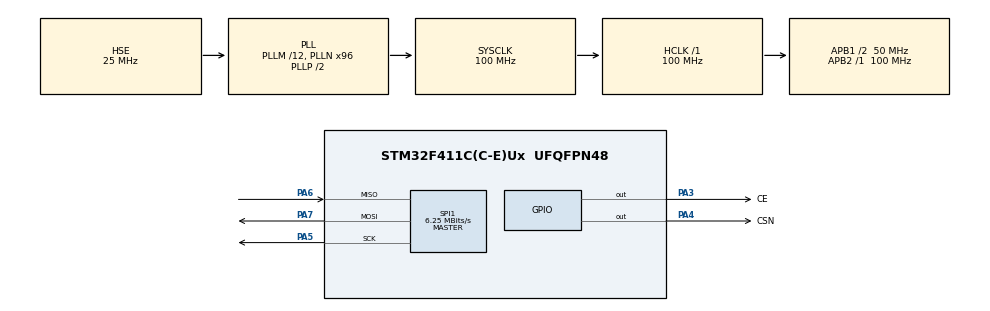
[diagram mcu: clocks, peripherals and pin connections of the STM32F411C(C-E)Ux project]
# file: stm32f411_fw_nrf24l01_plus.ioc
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Mcu.Family=STM32F4
RCC.PLLSourceVirtual=RCC_PLLSOURCE_HSE
PC15-OSC32_OUT.Mode=LSE-External-Oscillator
PA6.Mode=Full_Duplex_Master
RCC.CortexFreq_Value=100000000
PA7.Mode=Full_Duplex_Master
SPI1.VirtualType=VM_MASTER
PH1\ -\ OSC_OUT.Mode=HSE-External-Oscillator
RCC.APB1CLKDivider=RCC_HCLK_DIV2
PC14-OSC32_IN.Signal=RCC_OSC32_IN
PA3.GPIO_Speed=GPIO_SPEED_FREQ_HIGH
RCC.SYSCLKSource=RCC_SYSCLKSOURCE_PLLCLK
ProjectManager.StackSize=0x400
PA13.Signal=SYS_JTMS-SWDIO
PH0\ -\ OSC_IN.Mode=HSE-External-Oscillator
PA4.PinState=GPIO_PIN_SET
PH0\ -\ OSC_IN.Signal=RCC_OSC_IN
ProjectManager.TargetToolchain=STM32CubeIDE
SPI1.Direction=SPI_DIRECTION_2LINES
RCC.HCLKFreq_Value=100000000
RCC.APB2TimFreq_Value=100000000
SPI1.CalculateBaudRate=6.25 MBits/s
PC15-OSC32_OUT.Signal=RCC_OSC32_OUT
RCC.AHBFreq_Value=100000000
PA5.Signal=SPI1_SCK
RCC.HSE_VALUE=25000000
PH1\ -\ OSC_OUT.Signal=RCC_OSC_OUT
board=custom
RCC.VCOOutputFreq_Value=200000000
PA4.GPIO_Speed=GPIO_SPEED_FREQ_HIGH
RCC.APB2Freq_Value=100000000
PC14-OSC32_IN.Mode=LSE-External-Oscillator
SPI1.Mode=SPI_MODE_MASTER
PA14.Mode=Serial_Wire
PA13.Mode=Serial_Wire
Mcu.Name=STM32F411C(C-E)Ux
RCC.48MHZClocksFreq_Value=50000000
PA4.Signal=GPIO_Output
RCC.SYSCLKFreq_VALUE=100000000
Mcu.Package=UFQFPN48
PA6.Signal=SPI1_MISO
PA14.Signal=SYS_JTCK-SWCLK
ProjectManager.HeapSize=0x200
RCC.HSI_VALUE=16000000
NVIC.PriorityGroup=NVIC_PRIORITYGROUP_4
RCC.PLLM=12
RCC.PLLN=96
RCC.APB1TimFreq_Value=100000000
RCC.APB1Freq_Value=50000000
SPI1.BaudRatePrescaler=SPI_BAUDRATEPRESCALER_16
PA4.GPIO_Label=CSN
PA3.GPIO_Label=CE
PA3.Signal=GPIO_Output
PA5.Mode=Full_Duplex_Master
PA7.Signal=SPI1_MOSI

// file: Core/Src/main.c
/* USER CODE BEGIN Header */
/**
  ******************************************************************************
  * @file           : main.c
  * @brief          : Main program body
  ******************************************************************************
  * @attention
  *
  * <h2><center>&copy; Copyright (c) 2021 STMicroelectronics.
  * All rights reserved.</center></h2>
  *
  * This software component is licensed by ST under BSD 3-Clause license,
  * the "License"; You may not use this file except in compliance with the
  * License. You may obtain a copy of the License at:
  *                        opensource.org/licenses/BSD-3-Clause
  *
  ******************************************************************************
  */
/* USER CODE END Header */
#include "main.h"
#include "spi.h"
#include "gpio.h"

/* USER CODE BEGIN Includes */

#include "nrf24l01p.h"

/* USER CODE END Includes */

/* USER CODE BEGIN PV */

uint8_t reg_value_temp1;
uint8_t reg_value_temp2;

/* USER CODE END PV */

void SystemClock_Config(void);

int main(void)
{

  /* MCU Configuration--------------------------------------------------------*/

  /* Reset of all peripherals, Initializes the Flash interface and the Systick. */
  HAL_Init();

  /* Configure the system clock */
  SystemClock_Config();

  /* Initialize all configured peripherals */
  MX_GPIO_Init();
  MX_SPI1_Init();
  /* USER CODE BEGIN 2 */

  reg_value_temp1 = nrf24l01p_cmd_r_register(NRF24L01P_REG_CONFIG);
  //nrf24l01p_power_up();
  //nrf24l01p_power_down();
  reg_value_temp2 = nrf24l01p_cmd_r_register(NRF24L01P_REG_CONFIG);

  /* USER CODE END 2 */

  /* Infinite loop */
  while (1)
  {

  }
}

void SystemClock_Config(void)
{
  RCC_OscInitTypeDef RCC_OscInitStruct = {0};
  RCC_ClkInitTypeDef RCC_ClkInitStruct = {0};

  /** Configure the main internal regulator output voltage
  */
  __HAL_RCC_PWR_CLK_ENABLE();
  __HAL_PWR_VOLTAGESCALING_CONFIG(PWR_REGULATOR_VOLTAGE_SCALE1);
  /** Initializes the RCC Oscillators according to the specified parameters
  * in the RCC_OscInitTypeDef structure.
  */
  RCC_OscInitStruct.OscillatorType = RCC_OSCILLATORTYPE_HSE;
  RCC_OscInitStruct.HSEState = RCC_HSE_ON;
  RCC_OscInitStruct.PLL.PLLState = RCC_PLL_ON;
  RCC_OscInitStruct.PLL.PLLSource = RCC_PLLSOURCE_HSE;
  RCC_OscInitStruct.PLL.PLLM = 12;
  RCC_OscInitStruct.PLL.PLLN = 96;
  RCC_OscInitStruct.PLL.PLLP = RCC_PLLP_DIV2;
  RCC_OscInitStruct.PLL.PLLQ = 4;
  if (HAL_RCC_OscConfig(&RCC_OscInitStruct) != HAL_OK)
  {
    Error_Handler();
  }
  /** Initializes the CPU, AHB and APB buses clocks
  */
  RCC_ClkInitStruct.ClockType = RCC_CLOCKTYPE_HCLK|RCC_CLOCKTYPE_SYSCLK
                              |RCC_CLOCKTYPE_PCLK1|RCC_CLOCKTYPE_PCLK2;
  RCC_ClkInitStruct.SYSCLKSource = RCC_SYSCLKSOURCE_PLLCLK;
  RCC_ClkInitStruct.AHBCLKDivider = RCC_SYSCLK_DIV1;
  RCC_ClkInitStruct.APB1CLKDivider = RCC_HCLK_DIV2;
  RCC_ClkInitStruct.APB2CLKDivider = RCC_HCLK_DIV1;

  if (HAL_RCC_ClockConfig(&RCC_ClkInitStruct, FLASH_LATENCY_3) != HAL_OK)
  {
    Error_Handler();
  }
}

void Error_Handler(void)
{
  __disable_irq();
  while (1)
  {
  }
}

/************************ (C) COPYRIGHT STMicroelectronics *****END OF FILE****/
